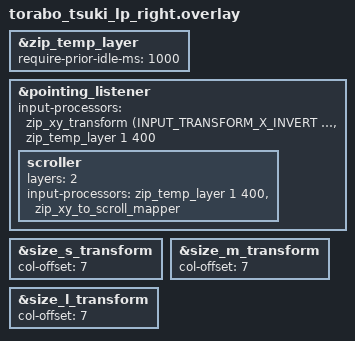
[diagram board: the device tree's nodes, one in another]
#include "torabo_tsuki_lp.dtsi"
#include <input/processors.dtsi>
#include <dt-bindings/zmk/input_transform.h>

//キー入力中のトラックボール接触によるオートマウスレイヤ起動の防止．(2026.08.01)
&zip_temp_layer {
    require-prior-idle-ms = <1000>;
};

&pointing_listener {
    input-processors = <
        &zip_xy_transform (INPUT_TRANSFORM_X_INVERT | INPUT_TRANSFORM_Y_INVERT)

        // オートマウスレイヤ追加(2026.07.20)
        &zip_temp_layer 1 400
    >;

    //トラックボール移動をスクロールに変換(2026.07.31)
    scroller {
        layers = <2>;
        input-processors = <
            &zip_temp_layer 1 400        //オートマウスレイヤを優先させるためのおまじない
            &zip_xy_to_scroll_mapper
        >;
    };
};

&size_s_transform {
    col-offset = <7>;
};

&size_m_transform {
    col-offset = <7>;
};

&size_l_transform {
    col-offset = <7>;
};
